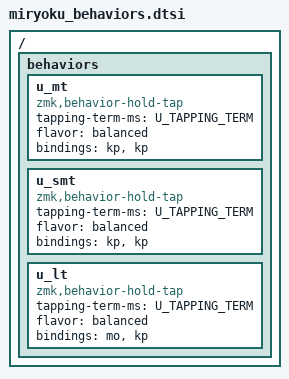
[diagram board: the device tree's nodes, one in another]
// Copyright 2022 Manna Harbour
// https://github.com/manna-harbour/miryoku

/ {
  behaviors {
    u_mt: u_mt { //home row mods
      compatible = "zmk,behavior-hold-tap";
      #binding-cells = <2>;
      tapping-term-ms = <U_TAPPING_TERM>;
      flavor = "balanced";
      bindings = <&kp>, <&kp>;
    };
    u_smt: u_smt { //home row mods
    compatible = "zmk,behavior-hold-tap";
      #binding-cells = <2>;
      tapping-term-ms = <U_TAPPING_TERM>;
      flavor = "balanced";
      bindings = <&kp>, <&kp>;
    };
    u_lt: u_lt { //layer tap
      compatible = "zmk,behavior-hold-tap";
      #binding-cells = <2>;
      tapping-term-ms = <U_TAPPING_TERM>;
      flavor = "balanced";
      bindings = <&mo>, <&kp>;
    };
  };
  // shift -> balance
  // ctrl+alt+super -> balanced
  // layer keys + shift -> hold-preferred
};
